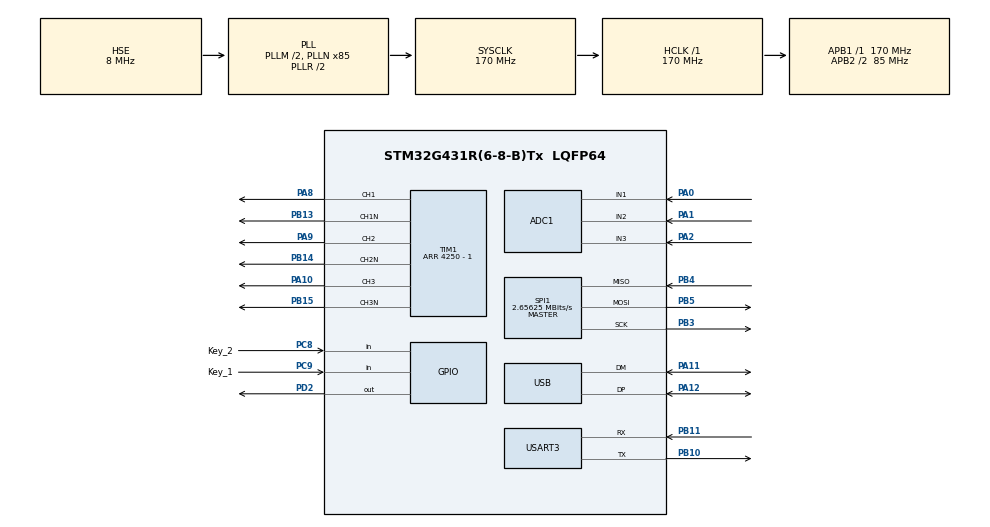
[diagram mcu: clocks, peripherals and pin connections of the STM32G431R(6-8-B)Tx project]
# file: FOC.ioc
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ADC1.ContinuousConvMode=ENABLE
ADC1.EOCSelection=ADC_EOC_SEQ_CONV
ADC1.EnableInjectedConversion=ENABLE
ADC1.EnableInjectedOversampling=ENABLE
ADC1.EnableRegularConversion=DISABLE
ADC1.ExternalTrigInjecConv=ADC_EXTERNALTRIGINJEC_T1_CC4
ADC1.InjNumberOfConversion=3
ADC1.InjOversamplingRatio=ADC_OVERSAMPLING_RATIO_4
ADC1.InjOversamplingRightShift=ADC_RIGHTBITSHIFT_2
ADC1.InjectedChannel-2\#ChannelInjectedConversion=ADC_CHANNEL_1
ADC1.InjectedChannel-3\#ChannelInjectedConversion=ADC_CHANNEL_2
ADC1.InjectedChannel-4\#ChannelInjectedConversion=ADC_CHANNEL_3
ADC1.InjectedOffsetNumber-2\#ChannelInjectedConversion=ADC_OFFSET_NONE
ADC1.InjectedOffsetNumber-3\#ChannelInjectedConversion=ADC_OFFSET_NONE
ADC1.InjectedOffsetNumber-4\#ChannelInjectedConversion=ADC_OFFSET_NONE
ADC1.InjectedRank-2\#ChannelInjectedConversion=1
ADC1.InjectedRank-3\#ChannelInjectedConversion=2
ADC1.InjectedRank-4\#ChannelInjectedConversion=3
ADC1.InjectedSamplingTime-2\#ChannelInjectedConversion=ADC_SAMPLETIME_2CYCLES_5
ADC1.InjectedSamplingTime-3\#ChannelInjectedConversion=ADC_SAMPLETIME_2CYCLES_5
ADC1.InjectedSamplingTime-4\#ChannelInjectedConversion=ADC_SAMPLETIME_2CYCLES_5
ADC1.Rank2_Channel=ADC_CHANNEL_2
ADC1.Rank3_Channel=ADC_CHANNEL_3
ADC1.master=1
Mcu.Family=STM32G4
Mcu.Name=STM32G431R(6-8-B)Tx
Mcu.Package=LQFP64
NVIC.ADC1_2_IRQn=true\:0\:0\:false\:false\:true\:true\:true\:true
NVIC.CORDIC_IRQn=true\:0\:0\:false\:false\:true\:true\:true\:true
NVIC.PriorityGroup=NVIC_PRIORITYGROUP_4
NVIC.TIM1_UP_TIM16_IRQn=true\:2\:0\:true\:false\:true\:true\:true\:true
NVIC.TIM6_DAC_IRQn=true\:6\:0\:true\:false\:true\:true\:true\:true
NVIC.TIM7_IRQn=true\:7\:0\:true\:false\:true\:true\:true\:true
NVIC.USART3_IRQn=true\:0\:0\:false\:false\:true\:true\:true\:true
NVIC.USB_LP_IRQn=true\:0\:0\:false\:false\:true\:false\:true\:true
PA0.Mode=IN1-Single-Ended
PA0.Signal=ADC1_IN1
PA1.Mode=IN2-Single-Ended
PA1.Signal=ADC1_IN2
PA10.Signal=S_TIM1_CH3
PA11.Mode=Device
PA11.Signal=USB_DM
PA12.Mode=Device
PA12.Signal=USB_DP
PA13.Mode=Serial_Wire
PA13.Signal=SYS_JTMS-SWDIO
PA14.Mode=Serial_Wire
PA14.Signal=SYS_JTCK-SWCLK
PA2.Mode=IN3-Single-Ended
PA2.Signal=ADC1_IN3
PA8.Signal=S_TIM1_CH1
PA9.Signal=S_TIM1_CH2
PB10.Mode=Asynchronous
PB10.Signal=USART3_TX
PB11.Mode=Asynchronous
PB11.Signal=USART3_RX
PB13.Mode=PWM Generation1 CH1 CH1N
PB13.Signal=TIM1_CH1N
PB14.Mode=PWM Generation2 CH2 CH2N
PB14.Signal=TIM1_CH2N
PB15.Mode=PWM Generation3 CH3 CH3N
PB15.Signal=TIM1_CH3N
PB3.Mode=Full_Duplex_Master
PB3.Signal=SPI1_SCK
PB4.Mode=Full_Duplex_Master
PB4.Signal=SPI1_MISO
PB5.Mode=Full_Duplex_Master
PB5.Signal=SPI1_MOSI
PC8.GPIO_Label=Key_2
PC8.GPIO_PuPd=GPIO_PULLUP
PC8.Signal=GPIO_Input
PC9.GPIO_Label=Key_1
PC9.GPIO_PuPd=GPIO_PULLUP
PC9.Signal=GPIO_Input
PD2.GPIO_Speed=GPIO_SPEED_FREQ_HIGH
PD2.PinState=GPIO_PIN_SET
PD2.Signal=GPIO_Output
PF0-OSC_IN.Mode=HSE-External-Oscillator
PF0-OSC_IN.Signal=RCC_OSC_IN
PF1-OSC_OUT.Mode=HSE-External-Oscillator
PF1-OSC_OUT.Signal=RCC_OSC_OUT
ProjectManager.HeapSize=0x200
ProjectManager.StackSize=0x400
ProjectManager.TargetToolchain=CMake
RCC.ADC12Freq_Value=170000000
RCC.AHBFreq_Value=170000000
RCC.APB1Freq_Value=170000000
RCC.APB1TimFreq_Value=170000000
RCC.APB2CLKDivider=RCC_HCLK_DIV2
RCC.APB2Freq_Value=85000000
RCC.APB2TimFreq_Value=170000000
RCC.CK48CLockSelection=RCC_USBCLKSOURCE_HSI48
RCC.CortexFreq_Value=170000000
RCC.EXTERNAL_CLOCK_VALUE=12288000
RCC.HCLKFreq_Value=170000000
RCC.HSE_VALUE=8000000
RCC.HSI48_VALUE=48000000
RCC.HSI_VALUE=16000000
RCC.LSE_VALUE=32768
RCC.PLLM=RCC_PLLM_DIV2
RCC.PLLN=85
RCC.PLLSourceVirtual=RCC_PLLSOURCE_HSE
RCC.SYSCLKFreq_VALUE=170000000
RCC.SYSCLKSource=RCC_SYSCLKSOURCE_PLLCLK
RCC.USBFreq_Value=48000000
RCC.VCOOutputFreq_Value=340000000
SH.S_TIM1_CH1.0=TIM1_CH1,PWM Generation1 CH1 CH1N
SH.S_TIM1_CH2.0=TIM1_CH2,PWM Generation2 CH2 CH2N
SH.S_TIM1_CH3.0=TIM1_CH3,PWM Generation3 CH3 CH3N
SPI1.BaudRatePrescaler=SPI_BAUDRATEPRESCALER_32
SPI1.CLKPhase=SPI_PHASE_2EDGE
SPI1.CalculateBaudRate=2.65625 MBits/s
SPI1.DataSize=SPI_DATASIZE_8BIT
SPI1.Direction=SPI_DIRECTION_2LINES
SPI1.Mode=SPI_MODE_MASTER
SPI1.VirtualType=VM_MASTER
TIM1.AutoReloadPreload=TIM_AUTORELOAD_PRELOAD_ENABLE
TIM1.Channel-PWM\ Generation1\ CH1\ CH1N=TIM_CHANNEL_1
TIM1.Channel-PWM\ Generation2\ CH2\ CH2N=TIM_CHANNEL_2
TIM1.Channel-PWM\ Generation3\ CH3\ CH3N=TIM_CHANNEL_3
TIM1.Channel-PWM\ Generation4\ No\ Output=TIM_CHANNEL_4
TIM1.CounterMode=TIM_COUNTERMODE_CENTERALIGNED2
TIM1.DeadTime=51
TIM1.PeriodNoDither=4250 - 1
TIM1.TIM_MasterSlaveMode=TIM_MASTERSLAVEMODE_ENABLE
TIM6.AutoReloadPreload=TIM_AUTORELOAD_PRELOAD_ENABLE
TIM6.PeriodNoDither=1000 - 1
TIM6.Prescaler=170 - 1
TIM7.AutoReloadPreload=TIM_AUTORELOAD_PRELOAD_ENABLE
TIM7.PeriodNoDither=4250 - 1
TIM7.Prescaler=0
USART3.VirtualMode-Asynchronous=VM_ASYNC
USB_DEVICE.CLASS_NAME_FS=CDC
USB_DEVICE.VirtualMode=Cdc
USB_DEVICE.VirtualModeFS=Cdc_FS
VP_CORDIC_VS_CORDIC.Mode=CORDIC_Activate
VP_SYS_VS_DBSignals.Mode=DisableDeadBatterySignals
VP_TIM1_VS_ClockSourceINT.Mode=Internal
VP_TIM1_VS_no_output4.Mode=PWM Generation4 No Output
VP_TIM6_VS_ClockSourceINT.Mode=Enable_Timer
VP_TIM7_VS_ClockSourceINT.Mode=Enable_Timer
VP_USB_DEVICE_VS_USB_DEVICE_CDC_FS.Mode=CDC_FS
board=custom

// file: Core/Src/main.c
/* USER CODE BEGIN Header */
/**
  ******************************************************************************
  * @file           : main.c
  * @brief          : Main program body
  ******************************************************************************
  * @attention
  *
  * Copyright (c) 2026 STMicroelectronics.
  * All rights reserved.
  *
  * This software is licensed under terms that can be found in the LICENSE file
  * in the root directory of this software component.
  * If no LICENSE file comes with this software, it is provided AS-IS.
  *
  ******************************************************************************
  */
/* USER CODE END Header */
#include "main.h"
#include "adc.h"
#include "cordic.h"
#include "spi.h"
#include "tim.h"
#include "usart.h"
#include "usb_device.h"
#include "gpio.h"

/* USER CODE BEGIN Includes */
#include "State_Machine.h"
#include "Timer.h"
/* USER CODE END Includes */

/* USER CODE BEGIN PV */
Timer_t Timer_test;
/* USER CODE END PV */

void SystemClock_Config(void);

/* USER CODE BEGIN 0 */
void Timer_Test_PeriodElapsedCallback(Timer_t *timer){
  if(timer == &Timer_test){

}
}
/* USER CODE END 0 */

int main(void)
{

  /* MCU Configuration--------------------------------------------------------*/

  /* Reset of all peripherals, Initializes the Flash interface and the Systick. */
  HAL_Init();

  /* Configure the system clock */
  SystemClock_Config();

  /* Initialize all configured peripherals */
  MX_GPIO_Init();
  MX_TIM6_Init();
  MX_USB_Device_Init();
  MX_TIM7_Init();
  MX_TIM1_Init();
  MX_ADC1_Init();
  MX_SPI1_Init();
  MX_USART3_UART_Init();
  MX_CORDIC_Init();
  /* USER CODE BEGIN 2 */
  State_Machine_Init();
  /* USER CODE END 2 */

  /* Infinite loop */
  while (1)
  {

    /* USER CODE BEGIN 3 */
    State_Machine_Loop();
  }
  /* USER CODE END 3 */
}

void SystemClock_Config(void)
{
  RCC_OscInitTypeDef RCC_OscInitStruct = {0};
  RCC_ClkInitTypeDef RCC_ClkInitStruct = {0};

  /** Configure the main internal regulator output voltage
  */
  HAL_PWREx_ControlVoltageScaling(PWR_REGULATOR_VOLTAGE_SCALE1_BOOST);

  /** Initializes the RCC Oscillators according to the specified parameters
  * in the RCC_OscInitTypeDef structure.
  */
  RCC_OscInitStruct.OscillatorType = RCC_OSCILLATORTYPE_HSI48|RCC_OSCILLATORTYPE_HSE;
  RCC_OscInitStruct.HSEState = RCC_HSE_ON;
  RCC_OscInitStruct.HSI48State = RCC_HSI48_ON;
  RCC_OscInitStruct.PLL.PLLState = RCC_PLL_ON;
  RCC_OscInitStruct.PLL.PLLSource = RCC_PLLSOURCE_HSE;
  RCC_OscInitStruct.PLL.PLLM = RCC_PLLM_DIV2;
  RCC_OscInitStruct.PLL.PLLN = 85;
  RCC_OscInitStruct.PLL.PLLP = RCC_PLLP_DIV2;
  RCC_OscInitStruct.PLL.PLLQ = RCC_PLLQ_DIV2;
  RCC_OscInitStruct.PLL.PLLR = RCC_PLLR_DIV2;
  if (HAL_RCC_OscConfig(&RCC_OscInitStruct) != HAL_OK)
  {
    Error_Handler();
  }

  /** Initializes the CPU, AHB and APB buses clocks
  */
  RCC_ClkInitStruct.ClockType = RCC_CLOCKTYPE_HCLK|RCC_CLOCKTYPE_SYSCLK
                              |RCC_CLOCKTYPE_PCLK1|RCC_CLOCKTYPE_PCLK2;
  RCC_ClkInitStruct.SYSCLKSource = RCC_SYSCLKSOURCE_PLLCLK;
  RCC_ClkInitStruct.AHBCLKDivider = RCC_SYSCLK_DIV1;
  RCC_ClkInitStruct.APB1CLKDivider = RCC_HCLK_DIV1;
  RCC_ClkInitStruct.APB2CLKDivider = RCC_HCLK_DIV2;

  if (HAL_RCC_ClockConfig(&RCC_ClkInitStruct, FLASH_LATENCY_4) != HAL_OK)
  {
    Error_Handler();
  }
}

void Error_Handler(void)
{
  __disable_irq();
  while (1)
  {
  }
}
